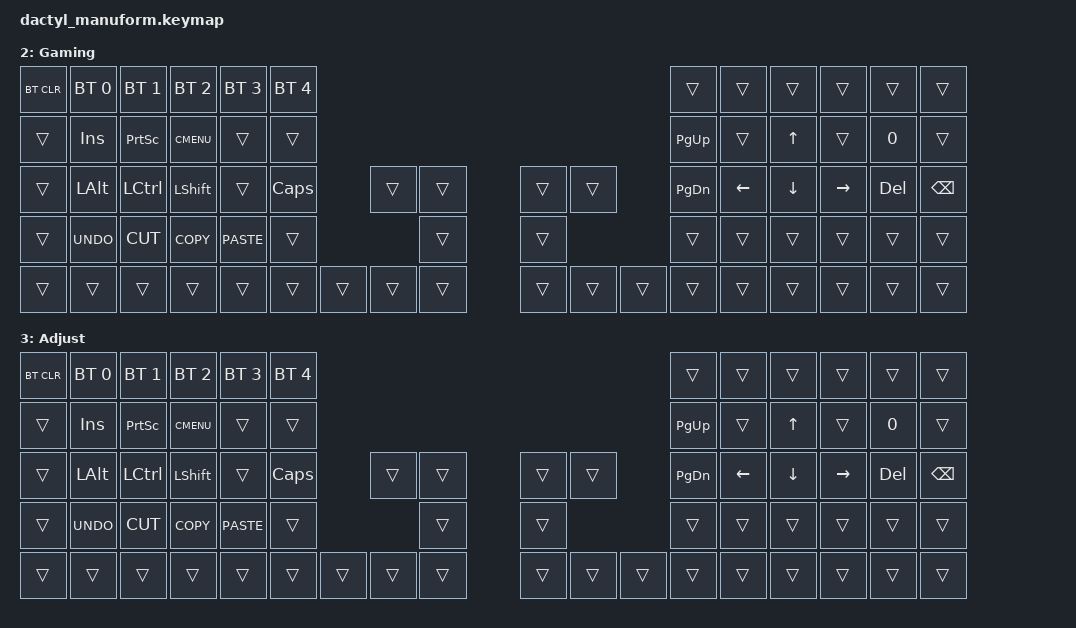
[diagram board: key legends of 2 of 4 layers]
#include <behaviors.dtsi>
#include <dt-bindings/zmk/keys.h>
#include <dt-bindings/zmk/bt.h>
#include <dt-bindings/zmk/outputs.h>

#define DEFAULT 0
#define LOWER   1
#define RAISE   2
#define ADJUST  3





/ {


    keymap {
        compatible = "zmk,keymap";
        default_layer {
            display-name = "Default";
            bindings = <
    &kp ESC        &kp N1    &kp N2   &kp N3    &kp N4    &kp N5                                                                              &kp N6  &kp N7        &kp N8    &kp N9    &kp N0   &kp MINUS
    &kp TAB        &kp Q     &kp W    &kp E     &kp R     &kp T                                                                               &kp Y   &kp U         &kp I     &kp O     &kp P    &kp BSLH
    &kp CLCK       &kp A     &kp S    &kp D     &kp F     &kp G            &kp RIGHT &kp PAUS             &kp INSERT &kp LEFT                &kp H   &kp J         &kp K     &kp L     &kp SEMI &kp SQT
    &kp LSHFT      &kp Z     &kp X    &kp C     &kp V     &kp B                      &kp SLCK              &kp HOME                           &kp N   &kp M         &kp COMMA &kp DOT   &kp FSLH &kp PG_UP
    &kp LCTRL      &kp LGUI  &kp LALT &kp GRAVE &mo RAISE       &kp ENTER  &kp SPACE &kp DELETE            &kp END &kp BSPC &kp RSHFT                 &mo LOWER     &kp EQUAL &kp LBKT  &kp RBKT &kp PG_DN
                                                         
            >;
        };
        lower_layer {
            display-name = "Lower";
            bindings = <
    &trans    &kp F1    &kp F2    &kp F3      &kp F4    &kp F5                                                                                 &kp F6    &kp F7   &kp F8          &kp F9    &kp F10   &kp F11
    &kp GRAVE &kp N1    &kp N2    &kp N3      &kp N4    &kp N5                                                                                 &kp N6    &kp N7   &kp N8          &kp N9    &kp N0    &kp F12
    &trans    &kp EXCL  &kp AT    &kp HASH    &kp DLLR  &kp PRCNT             &trans &trans                         &trans &trans              &kp CARET &kp AMPS &kp KP_MULTIPLY &kp LPAR  &kp RPAR  &kp PIPE
    &trans    &kp KP_EQUAL &kp KP_MINUS &kp KP_PLUS &kp LBRC  &kp RBRC                     &trans                         &trans                     &kp LBKT  &kp RBKT &kp SEMI        &kp COLON &kp BSLH  &trans
    &trans    &trans    &trans    &trans      &trans                &trans   &trans  &trans                         &trans &trans  &trans      &trans    &trans   &trans          &trans    &trans    &trans 


            >;       };

        raise_layer {
            display-name = "Gaming";
            bindings = <
   &bt BT_CLR    &bt BT_SEL 0    &bt BT_SEL 1    &bt BT_SEL 2    &bt BT_SEL 3    &bt BT_SEL 4                                                                        &trans    &trans      &trans   &trans    &trans  &trans
&trans           &kp INS         &kp PSCRN       &kp K_CMENU     &trans          &trans                                                                              &kp PG_UP &trans      &kp UP   &trans    &kp N0  &trans
&trans           &kp LALT        &kp LCTRL       &kp LSHFT       &trans          &kp CLCK             &trans  &trans                        &trans  &trans           &kp PG_DN &kp LEFT    &kp DOWN &kp RIGHT &kp DEL &kp BSPC
&trans           &kp K_UNDO      &kp K_CUT       &kp K_COPY      &kp K_PASTE     &trans                       &trans                        &trans                   &trans    &trans      &trans   &trans    &trans  &trans  
&trans           &trans          &trans          &trans          &trans          &trans       &trans  &trans  &trans                        &trans  &trans  &trans   &trans    &trans      &trans   &trans    &trans  &trans   
            >;
        };

        
        adjust_layer {
            display-name = "Adjust";
            bindings = <
      &bt BT_CLR    &bt BT_SEL 0    &bt BT_SEL 1    &bt BT_SEL 2    &bt BT_SEL 3    &bt BT_SEL 4                                                                        &trans    &trans      &trans   &trans    &trans  &trans
&trans           &kp INS         &kp PSCRN       &kp K_CMENU     &trans          &trans                                                                              &kp PG_UP &trans      &kp UP   &trans    &kp N0  &trans
&trans           &kp LALT        &kp LCTRL       &kp LSHFT       &trans          &kp CLCK             &trans  &trans                        &trans  &trans           &kp PG_DN &kp LEFT    &kp DOWN &kp RIGHT &kp DEL &kp BSPC
&trans           &kp K_UNDO      &kp K_CUT       &kp K_COPY      &kp K_PASTE     &trans                       &trans                        &trans                   &trans    &trans      &trans   &trans    &trans  &trans  
&trans           &trans          &trans          &trans          &trans          &trans       &trans  &trans  &trans                        &trans  &trans  &trans   &trans    &trans      &trans   &trans    &trans  &trans  
            >;
        };
    };
};
